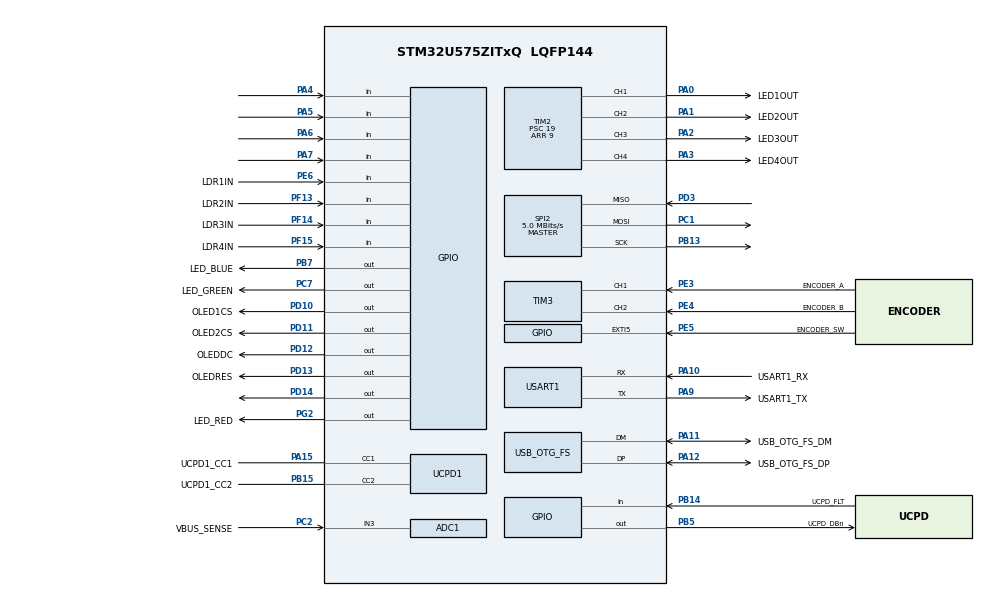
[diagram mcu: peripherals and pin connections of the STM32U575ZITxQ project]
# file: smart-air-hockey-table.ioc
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ADC1.NbrOfConversion=1
ADC1.Resolution=ADC_RESOLUTION_14B
ADC1.master=1
CORTEX_M33_NS.userName=CORTEX_M33
GPDMA1.CIRCULARMODE_GPDMACH0=DISABLE
GPDMA1.DATAHANDLING_GPDMACH0=ENABLE
GPDMA1.DATAHANDLING_GPDMACH1=ENABLE
GPDMA1.DATAHANDLING_GPDMACH2=ENABLE
GPDMA1.DATAHANDLING_GPDMACH3=ENABLE
GPDMA1.DESTDATAWIDTH_GPDMACH0=DMA_DEST_DATAWIDTH_WORD
GPDMA1.DESTDATAWIDTH_GPDMACH1=DMA_DEST_DATAWIDTH_WORD
GPDMA1.DESTDATAWIDTH_GPDMACH2=DMA_DEST_DATAWIDTH_WORD
GPDMA1.DESTDATAWIDTH_GPDMACH3=DMA_DEST_DATAWIDTH_WORD
GPDMA1.DIRECTION_GPDMACH0=DMA_MEMORY_TO_PERIPH
GPDMA1.DIRECTION_GPDMACH1=DMA_MEMORY_TO_PERIPH
GPDMA1.DIRECTION_GPDMACH2=DMA_MEMORY_TO_PERIPH
GPDMA1.DIRECTION_GPDMACH3=DMA_MEMORY_TO_PERIPH
GPDMA1.IPHANDLE_GPDMACH0-SIMPLEREQUEST_GPDMACH0=__NULL
GPDMA1.IPHANDLE_GPDMACH1-SIMPLEREQUEST_GPDMACH1=__NULL
GPDMA1.IPHANDLE_GPDMACH2-SIMPLEREQUEST_GPDMACH2=__NULL
GPDMA1.IPHANDLE_GPDMACH3-SIMPLEREQUEST_GPDMACH3=__NULL
GPDMA1.LINKALLOCATEDPORT_CIRCULAR_GPDMACH0=DMA_LINK_ALLOCATED_PORT1
GPDMA1.REQUEST_GPDMACH0=GPDMA1_REQUEST_TIM2_UP
GPDMA1.REQUEST_GPDMACH1=GPDMA1_REQUEST_TIM2_UP
GPDMA1.REQUEST_GPDMACH2=GPDMA1_REQUEST_TIM2_UP
GPDMA1.REQUEST_GPDMACH3=GPDMA1_REQUEST_TIM2_UP
GPDMA1.SRCDATAWIDTH_GPDMACH0=DMA_SRC_DATAWIDTH_BYTE
GPDMA1.SRCINC_GPDMACH0=DMA_SINC_INCREMENTED
GPDMA1.SRCINC_GPDMACH1=DMA_SINC_INCREMENTED
GPDMA1.SRCINC_GPDMACH2=DMA_SINC_INCREMENTED
GPDMA1.SRCINC_GPDMACH3=DMA_SINC_INCREMENTED
GPDMA1.TRANSFERALLOCATEDPORTSRC_GPDMACH0=DMA_SRC_ALLOCATED_PORT1
GPDMA1.TRANSFERALLOCATEDPORTSRC_GPDMACH1=DMA_SRC_ALLOCATED_PORT1
GPDMA1.TRANSFERALLOCATEDPORTSRC_GPDMACH2=DMA_SRC_ALLOCATED_PORT1
GPDMA1.TRANSFERALLOCATEDPORTSRC_GPDMACH3=DMA_SRC_ALLOCATED_PORT1
Mcu.Family=STM32U5
Mcu.Name=STM32U575ZITxQ
Mcu.Package=LQFP144
NVIC.EXTI5_IRQn=true\:3\:0\:true\:false\:true\:true\:true\:true
NVIC.GPDMA1_Channel0_IRQn=true\:3\:0\:true\:false\:true\:false\:true\:true
NVIC.GPDMA1_Channel1_IRQn=true\:3\:0\:true\:false\:true\:false\:true\:true
NVIC.GPDMA1_Channel2_IRQn=true\:3\:0\:true\:false\:true\:false\:true\:true
NVIC.GPDMA1_Channel3_IRQn=true\:3\:0\:true\:false\:true\:false\:true\:true
NVIC.OTG_FS_IRQn=true\:0\:0\:false\:false\:true\:true\:true\:true
NVIC.PriorityGroup=NVIC_PRIORITYGROUP_3
NVIC.TIM6_IRQn=true\:1\:0\:true\:false\:true\:true\:true\:true
NVIC.TIM7_IRQn=true\:2\:0\:true\:false\:true\:true\:true\:true
PA0.GPIO_Label=LED1OUT
PA0.Signal=S_TIM2_CH1
PA1.GPIO_Label=LED2OUT
PA1.Signal=S_TIM2_CH2
PA10.GPIO_Label=USART1_RX
PA10.GPIO_PuPd=GPIO_PULLDOWN
PA10.GPIO_Speed=GPIO_SPEED_FREQ_VERY_HIGH
PA10.Mode=Asynchronous
PA10.Signal=USART1_RX
PA11.GPIO_Label=USB_OTG_FS_DM
PA11.GPIO_Speed=GPIO_SPEED_FREQ_VERY_HIGH
PA11.Mode=Device_Only
PA11.Signal=USB_OTG_FS_DM
PA12.GPIO_Label=USB_OTG_FS_DP
PA12.GPIO_Speed=GPIO_SPEED_FREQ_VERY_HIGH
PA12.Mode=Device_Only
PA12.Signal=USB_OTG_FS_DP
PA13\ (JTMS/SWDIO).Mode=Trace_Asynchronous_SW
PA13\ (JTMS/SWDIO).Signal=DEBUG_JTMS-SWDIO
PA14\ (JTCK/SWCLK).Mode=Trace_Asynchronous_SW
PA14\ (JTCK/SWCLK).Signal=DEBUG_JTCK-SWCLK
PA15\ (JTDI).GPIO_Label=UCPD1_CC1
PA15\ (JTDI).Mode=Sink_AllSignals
PA15\ (JTDI).Signal=UCPD1_CC1
PA2.GPIO_Label=LED3OUT
PA2.Signal=S_TIM2_CH3
PA3.GPIO_Label=LED4OUT
PA3.Signal=S_TIM2_CH4
PA4.GPIO_PuPd=GPIO_PULLUP
PA4.Signal=GPIO_Input
PA5.GPIO_PuPd=GPIO_PULLUP
PA5.Signal=GPIO_Input
PA6.GPIO_PuPd=GPIO_PULLUP
PA6.Signal=GPIO_Input
PA7.GPIO_PuPd=GPIO_PULLUP
PA7.Signal=GPIO_Input
PA9.GPIO_Label=USART1_TX
PA9.GPIO_PuPd=GPIO_PULLDOWN
PA9.GPIO_Speed=GPIO_SPEED_FREQ_VERY_HIGH
PA9.Mode=Asynchronous
PA9.Signal=USART1_TX
PB13.Mode=Full_Duplex_Master
PB13.Signal=SPI2_SCK
PB14.GPIO_Label=UCPD_FLT
PB14.Signal=GPIO_Input
PB15.GPIO_Label=UCPD1_CC2
PB15.Mode=Sink_AllSignals
PB15.Signal=UCPD1_CC2
PB3\ (JTDO/TRACESWO).Mode=Trace_Asynchronous_SW
PB3\ (JTDO/TRACESWO).Signal=DEBUG_JTDO-SWO
PB5.GPIO_Label=UCPD_DBn
PB5.Signal=GPIO_Output
PB7.GPIO_Label=LED_BLUE
PB7.GPIO_ModeDefaultOutputPP=GPIO_MODE_OUTPUT_PP
PB7.GPIO_PuPd=GPIO_PULLUP
PB7.GPIO_Speed=GPIO_SPEED_FREQ_HIGH
PB7.Signal=GPIO_Output
PC1.Mode=Full_Duplex_Master
PC1.Signal=SPI2_MOSI
PC14-OSC32_IN\ (PC14).Mode=LSE-External-Oscillator
PC14-OSC32_IN\ (PC14).Signal=RCC_OSC32_IN
PC15-OSC32_OUT\ (PC15).Mode=LSE-External-Oscillator
PC15-OSC32_OUT\ (PC15).Signal=RCC_OSC32_OUT
PC2.GPIO_Label=VBUS_SENSE
PC2.Mode=IN3-Single-Ended
PC2.Signal=ADC1_IN3
PC7.GPIO_Label=LED_GREEN
PC7.GPIO_PuPd=GPIO_PULLUP
PC7.GPIO_Speed=GPIO_SPEED_FREQ_HIGH
PC7.Signal=GPIO_Output
PD10.GPIO_Label=OLED1CS
PD10.Signal=GPIO_Output
PD11.GPIO_Label=OLED2CS
PD11.Signal=GPIO_Output
PD12.GPIO_Label=OLEDDC
PD12.Signal=GPIO_Output
PD13.GPIO_Label=OLEDRES
PD13.Signal=GPIO_Output
PD14.Signal=GPIO_Output
PD3.Mode=Full_Duplex_Master
PD3.Signal=SPI2_MISO
PE3.GPIO_Label=ENCODER_A
PE3.GPIO_PuPd=GPIO_PULLUP
PE3.Signal=S_TIM3_CH1
PE4.GPIO_Label=ENCODER_B
PE4.GPIO_PuPd=GPIO_PULLUP
PE4.Signal=S_TIM3_CH2
PE5.GPIO_Label=ENCODER_SW
PE5.GPIO_ModeDefaultEXTI=GPIO_MODE_IT_FALLING
PE5.GPIO_PuPd=GPIO_PULLUP
PE5.Signal=GPXTI5
PE6.GPIO_Label=LDR1IN
PE6.Signal=GPIO_Input
PF13.GPIO_Label=LDR2IN
PF13.Signal=GPIO_Input
PF14.GPIO_Label=LDR3IN
PF14.Signal=GPIO_Input
PF15.GPIO_Label=LDR4IN
PF15.Signal=GPIO_Input
PG2.GPIO_Label=LED_RED
PG2.GPIO_ModeDefaultOutputPP=GPIO_MODE_OUTPUT_PP
PG2.GPIO_PuPd=GPIO_PULLUP
PG2.GPIO_Speed=GPIO_SPEED_FREQ_HIGH
PG2.Signal=GPIO_Output
PWR.PowerMode=PWR_SMPS_SUPPLY
ProjectManager.HeapSize=0x200
ProjectManager.StackSize=0x400
ProjectManager.TargetToolchain=STM32CubeIDE
RCC.ADCFreq_Value=16000000
RCC.AHBFreq_Value=160000000
RCC.APB1Freq_Value=160000000
RCC.APB1TimFreq_Value=160000000
RCC.APB2Freq_Value=160000000
RCC.APB2TimFreq_Value=160000000
RCC.APB3Freq_Value=160000000
RCC.CortexFreq_Value=160000000
RCC.DACCLockSelectionVirtual=RCC_DAC1CLKSOURCE_LSI
RCC.EPOD_VALUE=4000000
RCC.HCLKFreq_Value=160000000
RCC.HSE_VALUE=16000000
RCC.HSI48_VALUE=48000000
RCC.HSI_VALUE=16000000
RCC.LSIDIV_VALUE=32000
RCC.MSI_VALUE=4000000
RCC.PLLN=80
RCC.SYSCLKFreq_VALUE=160000000
RCC.SYSCLKSource=RCC_SYSCLKSOURCE_PLLCLK
RCC.USBFreq_Value=48000000
RCC.VCOOutputFreq_Value=320000000
SH.S_TIM2_CH1.0=TIM2_CH1,PWM Generation1 CH1
SH.S_TIM2_CH2.0=TIM2_CH2,PWM Generation2 CH2
SH.S_TIM2_CH3.0=TIM2_CH3,PWM Generation3 CH3
SH.S_TIM2_CH4.0=TIM2_CH4,PWM Generation4 CH4
SH.S_TIM3_CH1.0=TIM3_CH1,Encoder_Interface
SH.S_TIM3_CH2.0=TIM3_CH2,Encoder_Interface
SPI2.BaudRatePrescaler=SPI_BAUDRATEPRESCALER_32
SPI2.CalculateBaudRate=5.0 MBits/s
SPI2.DataSize=SPI_DATASIZE_8BIT
SPI2.Direction=SPI_DIRECTION_2LINES
SPI2.Mode=SPI_MODE_MASTER
SPI2.VirtualType=VM_MASTER
TIM2.Channel-PWM\ Generation1\ CH1=TIM_CHANNEL_1
TIM2.Channel-PWM\ Generation2\ CH2=TIM_CHANNEL_2
TIM2.Channel-PWM\ Generation3\ CH3=TIM_CHANNEL_3
TIM2.Channel-PWM\ Generation4\ CH4=TIM_CHANNEL_4
TIM2.PeriodNoDither=9
TIM2.Prescaler=19
TIM2.PulseNoDither_1=0
TIM2.TIM_MasterOutputTrigger=TIM_TRGO_RESET
TIM3.EncoderMode=TIM_ENCODERMODE_TI12
TIM3.IC1Filter=8
TIM3.IC2Filter=8
TIM6.PeriodNoDither=9
TIM6.Prescaler=15999
TIM7.PeriodNoDither=9
TIM7.Prescaler=15999
USART1.VirtualMode-Asynchronous=VM_ASYNC
USB_OTG_FS.VirtualMode=Device_Only
VP_GPDMA1_VS_GPDMACH0.Mode=SIMPLEREQUEST_GPDMACH0
VP_GPDMA1_VS_GPDMACH1.Mode=SIMPLEREQUEST_GPDMACH1
VP_GPDMA1_VS_GPDMACH2.Mode=SIMPLEREQUEST_GPDMACH2
VP_GPDMA1_VS_GPDMACH3.Mode=SIMPLEREQUEST_GPDMACH3
VP_ICACHE_VS_ICACHE.Mode=DirectMappedCache
VP_LPBAMQUEUE_VS_QUEUE.Mode=QUEUEMODE
VP_LPBAM_VS_SIG1.Mode=SmartRun
VP_LPBAM_VS_SIG4.Mode=LPDMA1
VP_MEMORYMAP_VS_MEMORYMAP.Mode=CurAppReg
VP_PWR_VS_DBSignals.Mode=DisableDeadBatterySignals
VP_PWR_VS_LPOM.Mode=PowerOptimisation
VP_PWR_VS_SECSignals.Mode=Security/Privilege
VP_PWR_Vdda.Mode=isolationVdda
VP_TIM2_VS_ClockSourceINT.Mode=Internal
VP_TIM6_VS_ClockSourceINT.Mode=Enable_Timer
VP_TIM7_VS_ClockSourceINT.Mode=Enable_Timer
board=NUCLEO-U575ZI-Q

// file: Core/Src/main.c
/* USER CODE BEGIN Header */
/**
  ******************************************************************************
  * @file           : main.c
  * @brief          : Main program body
  ******************************************************************************
  * @attention
  *
  * Copyright (c) 2023 STMicroelectronics.
  * All rights reserved.
  *
  * This software is licensed under terms that can be found in the LICENSE file
  * in the root directory of this software component.
  * If no LICENSE file comes with this software, it is provided AS-IS.
  *
  ******************************************************************************
  */
/* USER CODE END Header */
#include "main.h"

/* USER CODE BEGIN Includes */
#include "app_core.h"
/* USER CODE END Includes */

PCD_HandleTypeDef hpcd_USB_OTG_FS;

void SystemClock_Config(void);
static void SystemPower_Config(void);
static void MX_GPIO_Init(void);
static void MX_GPDMA1_Init(void);
static void MX_ICACHE_Init(void);
static void MX_UCPD1_Init(void);
static void MX_USART1_UART_Init(void);
static void MX_USB_OTG_FS_PCD_Init(void);
static void MX_MEMORYMAP_Init(void);
static void MX_TIM2_Init(void);
static void MX_ADC1_Init(void);
static void MX_SPI2_Init(void);
static void MX_TIM3_Init(void);
static void MX_TIM6_Init(void);
static void MX_TIM7_Init(void);

int main(void)
{

  /* MCU Configuration--------------------------------------------------------*/

  /* Reset of all peripherals, Initializes the Flash interface and the Systick. */
  HAL_Init();

  /* Enable PWR clock interface */

  LL_AHB3_GRP1_EnableClock(LL_AHB3_GRP1_PERIPH_PWR);

  /* USER CODE BEGIN Init */
  /* Enable the independent analog and I/Os supply */
  LL_PWR_EnableVDDA();

  /* USER CODE END Init */

  /* Configure the system clock */
  SystemClock_Config();

  /* Configure the System Power */
  SystemPower_Config();

  /* Initialize all configured peripherals */
  MX_GPIO_Init();
  MX_GPDMA1_Init();
  MX_ICACHE_Init();
  MX_UCPD1_Init();
  MX_USART1_UART_Init();
  MX_USB_OTG_FS_PCD_Init();
  MX_MEMORYMAP_Init();
  MX_TIM2_Init();
  MX_ADC1_Init();
  MX_SPI2_Init();
  MX_TIM3_Init();
  MX_TIM6_Init();
  MX_TIM7_Init();
  /* USER CODE BEGIN 2 */
  App_Init();
  /* USER CODE END 2 */

  /* Infinite loop */
  while (1)
  {

    /* USER CODE BEGIN 3 */
    asm("wfi");
  }
  /* USER CODE END 3 */
}

void SystemClock_Config(void)
{
  LL_FLASH_SetLatency(LL_FLASH_LATENCY_4);
  while(LL_FLASH_GetLatency()!= LL_FLASH_LATENCY_4)
  {
  }

  LL_PWR_SetRegulVoltageScaling(LL_PWR_REGU_VOLTAGE_SCALE1);
  while (LL_PWR_IsActiveFlag_VOS() == 0)
  {
  }
  LL_RCC_HSI_Enable();

   /* Wait till HSI is ready */
  while(LL_RCC_HSI_IsReady() != 1)
  {
  }

  LL_RCC_HSI_SetCalibTrimming(16);
  LL_RCC_HSI48_Enable();

   /* Wait till HSI48 is ready */
  while(LL_RCC_HSI48_IsReady() != 1)
  {
  }

  LL_RCC_MSIS_Enable();

   /* Wait till MSIS is ready */
  while(LL_RCC_MSIS_IsReady() != 1)
  {
  }

  LL_RCC_MSI_EnableRangeSelection();
  LL_RCC_MSIS_SetRange(LL_RCC_MSISRANGE_4);
  LL_RCC_MSI_SetCalibTrimming(16, LL_RCC_MSI_OSCILLATOR_1);
  LL_RCC_PLL1_ConfigDomain_SYS(LL_RCC_PLL1SOURCE_MSIS, 1, 80, 2);
  LL_RCC_PLL1_EnableDomain_SYS();
  LL_RCC_SetPll1EPodPrescaler(LL_RCC_PLL1MBOOST_DIV_1);
  LL_RCC_PLL1_SetVCOInputRange(LL_RCC_PLLINPUTRANGE_4_8);
  LL_RCC_PLL1_Enable();

   /* Wait till PLL is ready */
  while(LL_RCC_PLL1_IsReady() != 1)
  {
  }

   /* Intermediate AHB prescaler 2 when target frequency clock is higher than 80 MHz */
  LL_RCC_SetAHBPrescaler(LL_RCC_SYSCLK_DIV_2);

  LL_RCC_SetSysClkSource(LL_RCC_SYS_CLKSOURCE_PLL1);

   /* Wait till System clock is ready */
  while(LL_RCC_GetSysClkSource() != LL_RCC_SYS_CLKSOURCE_STATUS_PLL1)
  {
  }

  /* Insure 1us transition state at intermediate medium speed clock*/
  for (__IO uint32_t i = (160 >> 1); i !=0; i--);

  LL_RCC_SetAHBPrescaler(LL_RCC_SYSCLK_DIV_1);
  LL_RCC_SetAPB1Prescaler(LL_RCC_APB1_DIV_1);
  LL_RCC_SetAPB2Prescaler(LL_RCC_APB2_DIV_1);
  LL_RCC_SetAPB3Prescaler(LL_RCC_APB3_DIV_1);
  LL_SetSystemCoreClock(160000000);

   /* Update the time base */
  if (HAL_InitTick (TICK_INT_PRIORITY) != HAL_OK)
  {
    Error_Handler();
  }
}

/**
  * @brief Power Configuration
  * @retval None
  */
static void SystemPower_Config(void)
{

  /*
   * Switch to SMPS regulator instead of LDO
   */
  LL_PWR_SetRegulatorSupply(LL_PWR_SMPS_SUPPLY);

  while(LL_PWR_IsActiveFlag_REGULATOR()!=1)
  {
  }
}

static void MX_ADC1_Init(void)
{

  LL_ADC_CommonInitTypeDef ADC_CommonInitStruct = {0};
  LL_ADC_InitTypeDef ADC_InitStruct = {0};
  LL_ADC_REG_InitTypeDef ADC_REG_InitStruct = {0};

  LL_GPIO_InitTypeDef GPIO_InitStruct = {0};

  LL_RCC_SetADCDACClockSource(LL_RCC_ADCDAC_CLKSOURCE_HSI);

  /* Peripheral clock enable */
  LL_AHB2_GRP1_EnableClock(LL_AHB2_GRP1_PERIPH_ADC12);

  LL_AHB2_GRP1_EnableClock(LL_AHB2_GRP1_PERIPH_GPIOC);
  /**ADC1 GPIO Configuration
  PC2   ------> ADC1_IN3
  */
  GPIO_InitStruct.Pin = VBUS_SENSE_Pin;
  GPIO_InitStruct.Mode = LL_GPIO_MODE_ANALOG;
  GPIO_InitStruct.Pull = LL_GPIO_PULL_NO;
  LL_GPIO_Init(VBUS_SENSE_GPIO_Port, &GPIO_InitStruct);

  /** Common config
  */
  LL_ADC_SetTriggerFrequencyMode(ADC1, LL_ADC_TRIGGER_FREQ_HIGH);
  ADC_CommonInitStruct.CommonClock = LL_ADC_CLOCK_ASYNC_DIV1;
  LL_ADC_CommonInit(__LL_ADC_COMMON_INSTANCE(ADC1), &ADC_CommonInitStruct);
  ADC_InitStruct.Resolution = LL_ADC_RESOLUTION_14B;
  ADC_InitStruct.LowPowerMode = LL_ADC_LP_MODE_NONE;
  ADC_InitStruct.LeftBitShift = LL_ADC_LEFT_BIT_SHIFT_NONE;
  LL_ADC_Init(ADC1, &ADC_InitStruct);
  LL_ADC_SetGainCompensation(ADC1, 0);
  ADC_REG_InitStruct.SequencerLength = LL_ADC_REG_SEQ_SCAN_DISABLE;
  ADC_REG_InitStruct.SequencerDiscont = LL_ADC_REG_SEQ_DISCONT_DISABLE;
  ADC_REG_InitStruct.ContinuousMode = LL_ADC_REG_CONV_SINGLE;
  ADC_REG_InitStruct.Overrun = LL_ADC_REG_OVR_DATA_PRESERVED;
  ADC_REG_InitStruct.DataTransferMode = LL_ADC_REG_DR_TRANSFER;
  LL_ADC_REG_Init(ADC1, &ADC_REG_InitStruct);
  LL_ADC_SetOverSamplingScope(ADC1, LL_ADC_OVS_DISABLE);

  /* Disable ADC deep power down (enabled by default after reset state) */
  LL_ADC_DisableDeepPowerDown(ADC1);
  /* Enable ADC internal voltage regulator */
  LL_ADC_EnableInternalRegulator(ADC1);
  /* Delay for ADC internal voltage regulator stabilization. */
  /* Compute number of CPU cycles to wait for, from delay in us. */
  /* Note: Variable divided by 2 to compensate partially */
  /* CPU processing cycles (depends on compilation optimization). */
  /* Note: If system core clock frequency is below 200kHz, wait time */
  /* is only a few CPU processing cycles. */
  __IO uint32_t wait_loop_index;
  wait_loop_index = ((LL_ADC_DELAY_INTERNAL_REGUL_STAB_US * (SystemCoreClock / (100000 * 2))) / 10);
  while(wait_loop_index != 0)
  {
    wait_loop_index--;
  }

}

static void MX_GPDMA1_Init(void)
{

  /* Peripheral clock enable */
  LL_AHB1_GRP1_EnableClock(LL_AHB1_GRP1_PERIPH_GPDMA1);

  /* GPDMA1 interrupt Init */
  NVIC_SetPriority(GPDMA1_Channel0_IRQn, NVIC_EncodePriority(NVIC_GetPriorityGrouping(),3, 0));
  NVIC_EnableIRQ(GPDMA1_Channel0_IRQn);
  NVIC_SetPriority(GPDMA1_Channel1_IRQn, NVIC_EncodePriority(NVIC_GetPriorityGrouping(),3, 0));
  NVIC_EnableIRQ(GPDMA1_Channel1_IRQn);
  NVIC_SetPriority(GPDMA1_Channel2_IRQn, NVIC_EncodePriority(NVIC_GetPriorityGrouping(),3, 0));
  NVIC_EnableIRQ(GPDMA1_Channel2_IRQn);
  NVIC_SetPriority(GPDMA1_Channel3_IRQn, NVIC_EncodePriority(NVIC_GetPriorityGrouping(),3, 0));
  NVIC_EnableIRQ(GPDMA1_Channel3_IRQn);

}

static void MX_ICACHE_Init(void)
{

  /** Enable instruction cache in 1-way (direct mapped cache)
  */
  LL_ICACHE_SetMode(LL_ICACHE_1WAY);
  LL_ICACHE_Enable();

}

static void MX_MEMORYMAP_Init(void)
{

}

static void MX_SPI2_Init(void)
{

  LL_SPI_InitTypeDef SPI_InitStruct = {0};

  LL_GPIO_InitTypeDef GPIO_InitStruct = {0};

  LL_RCC_SetSPIClockSource(LL_RCC_SPI2_CLKSOURCE_SYSCLK);

  /* Peripheral clock enable */
  LL_APB1_GRP1_EnableClock(LL_APB1_GRP1_PERIPH_SPI2);

  LL_AHB2_GRP1_EnableClock(LL_AHB2_GRP1_PERIPH_GPIOC);
  LL_AHB2_GRP1_EnableClock(LL_AHB2_GRP1_PERIPH_GPIOB);
  LL_AHB2_GRP1_EnableClock(LL_AHB2_GRP1_PERIPH_GPIOD);
  /**SPI2 GPIO Configuration
  PC1   ------> SPI2_MOSI
  PB13   ------> SPI2_SCK
  PD3   ------> SPI2_MISO
  */
  GPIO_InitStruct.Pin = LL_GPIO_PIN_1;
  GPIO_InitStruct.Mode = LL_GPIO_MODE_ALTERNATE;
  GPIO_InitStruct.Speed = LL_GPIO_SPEED_FREQ_LOW;
  GPIO_InitStruct.OutputType = LL_GPIO_OUTPUT_PUSHPULL;
  GPIO_InitStruct.Pull = LL_GPIO_PULL_NO;
  GPIO_InitStruct.Alternate = LL_GPIO_AF_3;
  LL_GPIO_Init(GPIOC, &GPIO_InitStruct);

  GPIO_InitStruct.Pin = LL_GPIO_PIN_13;
  GPIO_InitStruct.Mode = LL_GPIO_MODE_ALTERNATE;
  GPIO_InitStruct.Speed = LL_GPIO_SPEED_FREQ_LOW;
  GPIO_InitStruct.OutputType = LL_GPIO_OUTPUT_PUSHPULL;
  GPIO_InitStruct.Pull = LL_GPIO_PULL_NO;
  GPIO_InitStruct.Alternate = LL_GPIO_AF_5;
  LL_GPIO_Init(GPIOB, &GPIO_InitStruct);

  GPIO_InitStruct.Pin = LL_GPIO_PIN_3;
  GPIO_InitStruct.Mode = LL_GPIO_MODE_ALTERNATE;
  GPIO_InitStruct.Speed = LL_GPIO_SPEED_FREQ_LOW;
  GPIO_InitStruct.OutputType = LL_GPIO_OUTPUT_PUSHPULL;
  GPIO_InitStruct.Pull = LL_GPIO_PULL_NO;
  GPIO_InitStruct.Alternate = LL_GPIO_AF_5;
  LL_GPIO_Init(GPIOD, &GPIO_InitStruct);

  /* SPI2 parameter configuration*/
  SPI_InitStruct.TransferDirection = LL_SPI_FULL_DUPLEX;
  SPI_InitStruct.Mode = LL_SPI_MODE_MASTER;
  SPI_InitStruct.DataWidth = LL_SPI_DATAWIDTH_8BIT;
  SPI_InitStruct.ClockPolarity = LL_SPI_POLARITY_LOW;
  SPI_InitStruct.ClockPhase = LL_SPI_PHASE_1EDGE;
  SPI_InitStruct.NSS = LL_SPI_NSS_SOFT;
  SPI_InitStruct.BaudRate = LL_SPI_BAUDRATEPRESCALER_DIV32;
  SPI_InitStruct.BitOrder = LL_SPI_MSB_FIRST;
  SPI_InitStruct.CRCCalculation = LL_SPI_CRCCALCULATION_DISABLE;
  SPI_InitStruct.CRCPoly = 0x7;
  LL_SPI_Init(SPI2, &SPI_InitStruct);
  LL_SPI_SetStandard(SPI2, LL_SPI_PROTOCOL_MOTOROLA);
  LL_SPI_EnableNSSPulseMgt(SPI2);

}

static void MX_TIM2_Init(void)
{

  LL_TIM_InitTypeDef TIM_InitStruct = {0};
  LL_TIM_OC_InitTypeDef TIM_OC_InitStruct = {0};

  LL_DMA_InitTypeDef DMA_InitStruct = {0};
  LL_GPIO_InitTypeDef GPIO_InitStruct = {0};

  /* Peripheral clock enable */
  LL_APB1_GRP1_EnableClock(LL_APB1_GRP1_PERIPH_TIM2);

  /* TIM2 DMA Init */

  /* GPDMA1_REQUEST_TIM2_UP Init */
  DMA_InitStruct.SrcAddress = 0x00000000U;
  DMA_InitStruct.DestAddress = 0x00000000U;
  DMA_InitStruct.Direction = LL_DMA_DIRECTION_MEMORY_TO_PERIPH;
  DMA_InitStruct.BlkHWRequest = LL_DMA_HWREQUEST_SINGLEBURST;
  DMA_InitStruct.DataAlignment = LL_DMA_DATA_ALIGN_ZEROPADD;
  DMA_InitStruct.SrcBurstLength = 1;
  DMA_InitStruct.DestBurstLength = 1;
  DMA_InitStruct.SrcDataWidth = LL_DMA_SRC_DATAWIDTH_BYTE;
  DMA_InitStruct.DestDataWidth = LL_DMA_DEST_DATAWIDTH_WORD;
  DMA_InitStruct.SrcIncMode = LL_DMA_SRC_INCREMENT;
  DMA_InitStruct.DestIncMode = LL_DMA_DEST_FIXED;
  DMA_InitStruct.Priority = LL_DMA_LOW_PRIORITY_LOW_WEIGHT;
  DMA_InitStruct.BlkDataLength = 0x00000000U;
  DMA_InitStruct.TriggerMode = LL_DMA_TRIGM_BLK_TRANSFER;
  DMA_InitStruct.TriggerPolarity = LL_DMA_TRIG_POLARITY_MASKED;
  DMA_InitStruct.TriggerSelection = 0x00000000U;
  DMA_InitStruct.Request = LL_GPDMA1_REQUEST_TIM2_UP;
  DMA_InitStruct.TransferEventMode = LL_DMA_TCEM_BLK_TRANSFER;
  DMA_InitStruct.SrcAllocatedPort = LL_DMA_SRC_ALLOCATED_PORT1;
  DMA_InitStruct.DestAllocatedPort = LL_DMA_DEST_ALLOCATED_PORT0;
  DMA_InitStruct.LinkAllocatedPort = LL_DMA_LINK_ALLOCATED_PORT1;
  DMA_InitStruct.LinkStepMode = LL_DMA_LSM_FULL_EXECUTION;
  DMA_InitStruct.LinkedListBaseAddr = 0x00000000U;
  DMA_InitStruct.LinkedListAddrOffset = 0x00000000U;
  LL_DMA_Init(GPDMA1, LL_DMA_CHANNEL_3, &DMA_InitStruct);

  /* GPDMA1_REQUEST_TIM2_UP Init */
  DMA_InitStruct.SrcAddress = 0x00000000U;
  DMA_InitStruct.DestAddress = 0x00000000U;
  DMA_InitStruct.Direction = LL_DMA_DIRECTION_MEMORY_TO_PERIPH;
  DMA_InitStruct.BlkHWRequest = LL_DMA_HWREQUEST_SINGLEBURST;
  DMA_InitStruct.DataAlignment = LL_DMA_DATA_ALIGN_ZEROPADD;
  DMA_InitStruct.SrcBurstLength = 1;
  DMA_InitStruct.DestBurstLength = 1;
  DMA_InitStruct.SrcDataWidth = LL_DMA_SRC_DATAWIDTH_BYTE;
  DMA_InitStruct.DestDataWidth = LL_DMA_DEST_DATAWIDTH_WORD;
  DMA_InitStruct.SrcIncMode = LL_DMA_SRC_INCREMENT;
  DMA_InitStruct.DestIncMode = LL_DMA_DEST_FIXED;
  DMA_InitStruct.Priority = LL_DMA_LOW_PRIORITY_LOW_WEIGHT;
  DMA_InitStruct.BlkDataLength = 0x00000000U;
  DMA_InitStruct.TriggerMode = LL_DMA_TRIGM_BLK_TRANSFER;
  DMA_InitStruct.TriggerPolarity = LL_DMA_TRIG_POLARITY_MASKED;
  DMA_InitStruct.TriggerSelection = 0x00000000U;
  DMA_InitStruct.Request = LL_GPDMA1_REQUEST_TIM2_UP;
  DMA_InitStruct.TransferEventMode = LL_DMA_TCEM_BLK_TRANSFER;
  DMA_InitStruct.SrcAllocatedPort = LL_DMA_SRC_ALLOCATED_PORT1;
  DMA_InitStruct.DestAllocatedPort = LL_DMA_DEST_ALLOCATED_PORT0;
  DMA_InitStruct.LinkAllocatedPort = LL_DMA_LINK_ALLOCATED_PORT1;
  DMA_InitStruct.LinkStepMode = LL_DMA_LSM_FULL_EXECUTION;
  DMA_InitStruct.LinkedListBaseAddr = 0x00000000U;
  DMA_InitStruct.LinkedListAddrOffset = 0x00000000U;
  LL_DMA_Init(GPDMA1, LL_DMA_CHANNEL_2, &DMA_InitStruct);

  /* GPDMA1_REQUEST_TIM2_UP Init */
  DMA_InitStruct.SrcAddress = 0x00000000U;
  DMA_InitStruct.DestAddress = 0x00000000U;
  DMA_InitStruct.Direction = LL_DMA_DIRECTION_MEMORY_TO_PERIPH;
  DMA_InitStruct.BlkHWRequest = LL_DMA_HWREQUEST_SINGLEBURST;
  DMA_InitStruct.DataAlignment = LL_DMA_DATA_ALIGN_ZEROPADD;
  DMA_InitStruct.SrcBurstLength = 1;
  DMA_InitStruct.DestBurstLength = 1;
  DMA_InitStruct.SrcDataWidth = LL_DMA_SRC_DATAWIDTH_BYTE;
  DMA_InitStruct.DestDataWidth = LL_DMA_DEST_DATAWIDTH_WORD;
  DMA_InitStruct.SrcIncMode = LL_DMA_SRC_INCREMENT;
  DMA_InitStruct.DestIncMode = LL_DMA_DEST_FIXED;
  DMA_InitStruct.Priority = LL_DMA_LOW_PRIORITY_LOW_WEIGHT;
  DMA_InitStruct.BlkDataLength = 0x00000000U;
  DMA_InitStruct.TriggerMode = LL_DMA_TRIGM_BLK_TRANSFER;
  DMA_InitStruct.TriggerPolarity = LL_DMA_TRIG_POLARITY_MASKED;
  DMA_InitStruct.TriggerSelection = 0x00000000U;
  DMA_InitStruct.Request = LL_GPDMA1_REQUEST_TIM2_UP;
  DMA_InitStruct.TransferEventMode = LL_DMA_TCEM_BLK_TRANSFER;
  DMA_InitStruct.SrcAllocatedPort = LL_DMA_SRC_ALLOCATED_PORT1;
  DMA_InitStruct.DestAllocatedPort = LL_DMA_DEST_ALLOCATED_PORT0;
  DMA_InitStruct.LinkAllocatedPort = LL_DMA_LINK_ALLOCATED_PORT1;
  DMA_InitStruct.LinkStepMode = LL_DMA_LSM_FULL_EXECUTION;
  DMA_InitStruct.LinkedListBaseAddr = 0x00000000U;
  DMA_InitStruct.LinkedListAddrOffset = 0x00000000U;
  LL_DMA_Init(GPDMA1, LL_DMA_CHANNEL_1, &DMA_InitStruct);

  /* GPDMA1_REQUEST_TIM2_UP Init */
  DMA_InitStruct.SrcAddress = 0x00000000U;
  DMA_InitStruct.DestAddress = 0x00000000U;
  DMA_InitStruct.Direction = LL_DMA_DIRECTION_MEMORY_TO_PERIPH;
  DMA_InitStruct.BlkHWRequest = LL_DMA_HWREQUEST_SINGLEBURST;
  DMA_InitStruct.DataAlignment = LL_DMA_DATA_ALIGN_ZEROPADD;
  DMA_InitStruct.SrcBurstLength = 1;
  DMA_InitStruct.DestBurstLength = 1;
  DMA_InitStruct.SrcDataWidth = LL_DMA_SRC_DATAWIDTH_BYTE;
  DMA_InitStruct.DestDataWidth = LL_DMA_DEST_DATAWIDTH_WORD;
  DMA_InitStruct.SrcIncMode = LL_DMA_SRC_INCREMENT;
  DMA_InitStruct.DestIncMode = LL_DMA_DEST_FIXED;
  DMA_InitStruct.Priority = LL_DMA_LOW_PRIORITY_LOW_WEIGHT;
  DMA_InitStruct.BlkDataLength = 0x00000000U;
  DMA_InitStruct.TriggerMode = LL_DMA_TRIGM_BLK_TRANSFER;
  DMA_InitStruct.TriggerPolarity = LL_DMA_TRIG_POLARITY_MASKED;
  DMA_InitStruct.TriggerSelection = 0x00000000U;
  DMA_InitStruct.Request = LL_GPDMA1_REQUEST_TIM2_UP;
  DMA_InitStruct.TransferEventMode = LL_DMA_TCEM_BLK_TRANSFER;
  DMA_InitStruct.SrcAllocatedPort = LL_DMA_SRC_ALLOCATED_PORT1;
  DMA_InitStruct.DestAllocatedPort = LL_DMA_DEST_ALLOCATED_PORT0;
  DMA_InitStruct.LinkAllocatedPort = LL_DMA_LINK_ALLOCATED_PORT1;
  DMA_InitStruct.LinkStepMode = LL_DMA_LSM_FULL_EXECUTION;
  DMA_InitStruct.LinkedListBaseAddr = 0x00000000U;
  DMA_InitStruct.LinkedListAddrOffset = 0x00000000U;
  LL_DMA_Init(GPDMA1, LL_DMA_CHANNEL_0, &DMA_InitStruct);

  TIM_InitStruct.Prescaler = 19;
  TIM_InitStruct.CounterMode = LL_TIM_COUNTERMODE_UP;
  TIM_InitStruct.Autoreload = 9;
  TIM_InitStruct.ClockDivision = LL_TIM_CLOCKDIVISION_DIV1;
  LL_TIM_Init(TIM2, &TIM_InitStruct);
  LL_TIM_DisableARRPreload(TIM2);
  LL_TIM_SetClockSource(TIM2, LL_TIM_CLOCKSOURCE_INTERNAL);
  LL_TIM_OC_EnablePreload(TIM2, LL_TIM_CHANNEL_CH1);
  TIM_OC_InitStruct.OCMode = LL_TIM_OCMODE_PWM1;
  TIM_OC_InitStruct.OCState = LL_TIM_OCSTATE_DISABLE;
  TIM_OC_InitStruct.OCNState = LL_TIM_OCSTATE_DISABLE;
  TIM_OC_InitStruct.CompareValue = 0;
  TIM_OC_InitStruct.OCPolarity = LL_TIM_OCPOLARITY_HIGH;
  LL_TIM_OC_Init(TIM2, LL_TIM_CHANNEL_CH1, &TIM_OC_InitStruct);
  LL_TIM_OC_DisableFast(TIM2, LL_TIM_CHANNEL_CH1);
  LL_TIM_OC_EnablePreload(TIM2, LL_TIM_CHANNEL_CH2);
  LL_TIM_OC_Init(TIM2, LL_TIM_CHANNEL_CH2, &TIM_OC_InitStruct);
  LL_TIM_OC_DisableFast(TIM2, LL_TIM_CHANNEL_CH2);
  LL_TIM_OC_EnablePreload(TIM2, LL_TIM_CHANNEL_CH3);
  LL_TIM_OC_Init(TIM2, LL_TIM_CHANNEL_CH3, &TIM_OC_InitStruct);
  LL_TIM_OC_DisableFast(TIM2, LL_TIM_CHANNEL_CH3);
  LL_TIM_OC_EnablePreload(TIM2, LL_TIM_CHANNEL_CH4);
  LL_TIM_OC_Init(TIM2, LL_TIM_CHANNEL_CH4, &TIM_OC_InitStruct);
  LL_TIM_OC_DisableFast(TIM2, LL_TIM_CHANNEL_CH4);
  LL_TIM_SetTriggerOutput(TIM2, LL_TIM_TRGO_RESET);
  LL_TIM_DisableMasterSlaveMode(TIM2);
  LL_AHB2_GRP1_EnableClock(LL_AHB2_GRP1_PERIPH_GPIOA);
  /**TIM2 GPIO Configuration
  PA0   ------> TIM2_CH1
  PA1   ------> TIM2_CH2
  PA2   ------> TIM2_CH3
  PA3   ------> TIM2_CH4
  */
  GPIO_InitStruct.Pin = LED1OUT_Pin|LED2OUT_Pin|LED3OUT_Pin|LED4OUT_Pin;
  GPIO_InitStruct.Mode = LL_GPIO_MODE_ALTERNATE;
  GPIO_InitStruct.Speed = LL_GPIO_SPEED_FREQ_LOW;
  GPIO_InitStruct.OutputType = LL_GPIO_OUTPUT_PUSHPULL;
  GPIO_InitStruct.Pull = LL_GPIO_PULL_NO;
  GPIO_InitStruct.Alternate = LL_GPIO_AF_1;
  LL_GPIO_Init(GPIOA, &GPIO_InitStruct);

}

static void MX_TIM3_Init(void)
{

  LL_TIM_InitTypeDef TIM_InitStruct = {0};

  LL_GPIO_InitTypeDef GPIO_InitStruct = {0};

  /* Peripheral clock enable */
  LL_APB1_GRP1_EnableClock(LL_APB1_GRP1_PERIPH_TIM3);

  LL_AHB2_GRP1_EnableClock(LL_AHB2_GRP1_PERIPH_GPIOE);
  /**TIM3 GPIO Configuration
  PE3   ------> TIM3_CH1
  PE4   ------> TIM3_CH2
  */
  GPIO_InitStruct.Pin = ENCODER_A_Pin|ENCODER_B_Pin;
  GPIO_InitStruct.Mode = LL_GPIO_MODE_ALTERNATE;
  GPIO_InitStruct.Speed = LL_GPIO_SPEED_FREQ_LOW;
  GPIO_InitStruct.OutputType = LL_GPIO_OUTPUT_PUSHPULL;
  GPIO_InitStruct.Pull = LL_GPIO_PULL_UP;
  GPIO_InitStruct.Alternate = LL_GPIO_AF_2;
  LL_GPIO_Init(GPIOE, &GPIO_InitStruct);

  TIM_InitStruct.Prescaler = 0;
  TIM_InitStruct.CounterMode = LL_TIM_COUNTERMODE_UP;
  TIM_InitStruct.Autoreload = 4.294967295E9;
  TIM_InitStruct.ClockDivision = LL_TIM_CLOCKDIVISION_DIV1;
  LL_TIM_Init(TIM3, &TIM_InitStruct);
  LL_TIM_DisableARRPreload(TIM3);
  LL_TIM_SetEncoderMode(TIM3, LL_TIM_ENCODERMODE_X4_TI12);
  LL_TIM_IC_SetActiveInput(TIM3, LL_TIM_CHANNEL_CH1, LL_TIM_ACTIVEINPUT_DIRECTTI);
  LL_TIM_IC_SetPrescaler(TIM3, LL_TIM_CHANNEL_CH1, LL_TIM_ICPSC_DIV1);
  LL_TIM_IC_SetFilter(TIM3, LL_TIM_CHANNEL_CH1, LL_TIM_IC_FILTER_FDIV8_N6);
  LL_TIM_IC_SetPolarity(TIM3, LL_TIM_CHANNEL_CH1, LL_TIM_IC_POLARITY_RISING);
  LL_TIM_IC_SetActiveInput(TIM3, LL_TIM_CHANNEL_CH2, LL_TIM_ACTIVEINPUT_DIRECTTI);
  LL_TIM_IC_SetPrescaler(TIM3, LL_TIM_CHANNEL_CH2, LL_TIM_ICPSC_DIV1);
  LL_TIM_IC_SetFilter(TIM3, LL_TIM_CHANNEL_CH2, LL_TIM_IC_FILTER_FDIV8_N6);
  LL_TIM_IC_SetPolarity(TIM3, LL_TIM_CHANNEL_CH2, LL_TIM_IC_POLARITY_RISING);
  LL_TIM_SetTriggerOutput(TIM3, LL_TIM_TRGO_RESET);
  LL_TIM_DisableMasterSlaveMode(TIM3);

}

static void MX_TIM6_Init(void)
{

  LL_TIM_InitTypeDef TIM_InitStruct = {0};

  /* Peripheral clock enable */
  LL_APB1_GRP1_EnableClock(LL_APB1_GRP1_PERIPH_TIM6);

  /* TIM6 interrupt Init */
  NVIC_SetPriority(TIM6_IRQn, NVIC_EncodePriority(NVIC_GetPriorityGrouping(),1, 0));
  NVIC_EnableIRQ(TIM6_IRQn);

  TIM_InitStruct.Prescaler = 15999;
  TIM_InitStruct.CounterMode = LL_TIM_COUNTERMODE_UP;
  TIM_InitStruct.Autoreload = 9;
  LL_TIM_Init(TIM6, &TIM_InitStruct);
  LL_TIM_DisableARRPreload(TIM6);
  LL_TIM_SetTriggerOutput(TIM6, LL_TIM_TRGO_RESET);
  LL_TIM_DisableMasterSlaveMode(TIM6);

}

static void MX_TIM7_Init(void)
{

  LL_TIM_InitTypeDef TIM_InitStruct = {0};

  /* Peripheral clock enable */
  LL_APB1_GRP1_EnableClock(LL_APB1_GRP1_PERIPH_TIM7);

  /* TIM7 interrupt Init */
  NVIC_SetPriority(TIM7_IRQn, NVIC_EncodePriority(NVIC_GetPriorityGrouping(),2, 0));
  NVIC_EnableIRQ(TIM7_IRQn);

  TIM_InitStruct.Prescaler = 15999;
  TIM_InitStruct.CounterMode = LL_TIM_COUNTERMODE_UP;
  TIM_InitStruct.Autoreload = 9;
  LL_TIM_Init(TIM7, &TIM_InitStruct);
  LL_TIM_DisableARRPreload(TIM7);
  LL_TIM_SetTriggerOutput(TIM7, LL_TIM_TRGO_RESET);
  LL_TIM_DisableMasterSlaveMode(TIM7);

}

static void MX_UCPD1_Init(void)
{

  LL_GPIO_InitTypeDef GPIO_InitStruct = {0};

  /* Peripheral clock enable */
  LL_APB1_GRP2_EnableClock(LL_APB1_GRP2_PERIPH_UCPD1);

  LL_AHB2_GRP1_EnableClock(LL_AHB2_GRP1_PERIPH_GPIOB);
  LL_AHB2_GRP1_EnableClock(LL_AHB2_GRP1_PERIPH_GPIOA);
  /**UCPD1 GPIO Configuration
  PB15   ------> UCPD1_CC2
  PA15 (JTDI)   ------> UCPD1_CC1
  */
  GPIO_InitStruct.Pin = UCPD1_CC2_Pin;
  GPIO_InitStruct.Mode = LL_GPIO_MODE_ANALOG;
  GPIO_InitStruct.Pull = LL_GPIO_PULL_NO;
  LL_GPIO_Init(UCPD1_CC2_GPIO_Port, &GPIO_InitStruct);

  GPIO_InitStruct.Pin = UCPD1_CC1_Pin;
  GPIO_InitStruct.Mode = LL_GPIO_MODE_ANALOG;
  GPIO_InitStruct.Pull = LL_GPIO_PULL_NO;
  LL_GPIO_Init(UCPD1_CC1_GPIO_Port, &GPIO_InitStruct);

}

static void MX_USART1_UART_Init(void)
{

  LL_USART_InitTypeDef USART_InitStruct = {0};

  LL_GPIO_InitTypeDef GPIO_InitStruct = {0};

  LL_RCC_SetUSARTClockSource(LL_RCC_USART1_CLKSOURCE_PCLK2);

  /* Peripheral clock enable */
  LL_APB2_GRP1_EnableClock(LL_APB2_GRP1_PERIPH_USART1);

  LL_AHB2_GRP1_EnableClock(LL_AHB2_GRP1_PERIPH_GPIOA);
  /**USART1 GPIO Configuration
  PA9   ------> USART1_TX
  PA10   ------> USART1_RX
  */
  GPIO_InitStruct.Pin = USART1_TX_Pin|USART1_RX_Pin;
  GPIO_InitStruct.Mode = LL_GPIO_MODE_ALTERNATE;
  GPIO_InitStruct.Speed = LL_GPIO_SPEED_FREQ_VERY_HIGH;
  GPIO_InitStruct.OutputType = LL_GPIO_OUTPUT_PUSHPULL;
  GPIO_InitStruct.Pull = LL_GPIO_PULL_DOWN;
  GPIO_InitStruct.Alternate = LL_GPIO_AF_7;
  LL_GPIO_Init(GPIOA, &GPIO_InitStruct);

  USART_InitStruct.PrescalerValue = LL_USART_PRESCALER_DIV1;
  USART_InitStruct.BaudRate = 115200;
  USART_InitStruct.DataWidth = LL_USART_DATAWIDTH_8B;
  USART_InitStruct.StopBits = LL_USART_STOPBITS_1;
  USART_InitStruct.Parity = LL_USART_PARITY_NONE;
  USART_InitStruct.TransferDirection = LL_USART_DIRECTION_TX_RX;
  USART_InitStruct.HardwareFlowControl = LL_USART_HWCONTROL_NONE;
  USART_InitStruct.OverSampling = LL_USART_OVERSAMPLING_16;
  LL_USART_Init(USART1, &USART_InitStruct);
  LL_USART_SetTXFIFOThreshold(USART1, LL_USART_FIFOTHRESHOLD_1_8);
  LL_USART_SetRXFIFOThreshold(USART1, LL_USART_FIFOTHRESHOLD_1_8);
  LL_USART_DisableFIFO(USART1);
  LL_USART_ConfigAsyncMode(USART1);
  LL_USART_Enable(USART1);

}

static void MX_USB_OTG_FS_PCD_Init(void)
{

  hpcd_USB_OTG_FS.Instance = USB_OTG_FS;
  hpcd_USB_OTG_FS.Init.dev_endpoints = 6;
  hpcd_USB_OTG_FS.Init.speed = PCD_SPEED_FULL;
  hpcd_USB_OTG_FS.Init.phy_itface = PCD_PHY_EMBEDDED;
  hpcd_USB_OTG_FS.Init.Sof_enable = DISABLE;
  hpcd_USB_OTG_FS.Init.low_power_enable = DISABLE;
  hpcd_USB_OTG_FS.Init.lpm_enable = DISABLE;
  hpcd_USB_OTG_FS.Init.battery_charging_enable = DISABLE;
  hpcd_USB_OTG_FS.Init.use_dedicated_ep1 = DISABLE;
  hpcd_USB_OTG_FS.Init.vbus_sensing_enable = DISABLE;
  hpcd_USB_OTG_FS.Init.dma_enable = DISABLE;
  if (HAL_PCD_Init(&hpcd_USB_OTG_FS) != HAL_OK)
  {
    Error_Handler();
  }

}

static void MX_GPIO_Init(void)
{
  LL_EXTI_InitTypeDef EXTI_InitStruct = {0};
  LL_GPIO_InitTypeDef GPIO_InitStruct = {0};

  /* GPIO Ports Clock Enable */
  LL_AHB2_GRP1_EnableClock(LL_AHB2_GRP1_PERIPH_GPIOE);
  LL_AHB2_GRP1_EnableClock(LL_AHB2_GRP1_PERIPH_GPIOC);
  LL_AHB2_GRP1_EnableClock(LL_AHB2_GRP1_PERIPH_GPIOA);
  LL_AHB2_GRP1_EnableClock(LL_AHB2_GRP1_PERIPH_GPIOF);
  LL_AHB2_GRP1_EnableClock(LL_AHB2_GRP1_PERIPH_GPIOB);
  LL_AHB2_GRP1_EnableClock(LL_AHB2_GRP1_PERIPH_GPIOD);
  LL_AHB2_GRP1_EnableClock(LL_AHB2_GRP1_PERIPH_GPIOG);
  LL_PWR_EnableVDDIO2();

  /**/
  LL_GPIO_ResetOutputPin(GPIOD, OLED1CS_Pin|OLED2CS_Pin|OLEDDC_Pin|OLEDRES_Pin
                          |LL_GPIO_PIN_14);

  /**/
  LL_GPIO_ResetOutputPin(LED_RED_GPIO_Port, LED_RED_Pin);

  /**/
  LL_GPIO_ResetOutputPin(LED_GREEN_GPIO_Port, LED_GREEN_Pin);

  /**/
  LL_GPIO_ResetOutputPin(GPIOB, UCPD_DBn_Pin|LED_BLUE_Pin);

  /**/
  LL_EXTI_SetEXTISource(LL_EXTI_EXTI_PORTE, LL_EXTI_EXTI_LINE5);

  /**/
  EXTI_InitStruct.Line_0_31 = LL_EXTI_LINE_5;
  EXTI_InitStruct.LineCommand = ENABLE;
  EXTI_InitStruct.Mode = LL_EXTI_MODE_IT;
  EXTI_InitStruct.Trigger = LL_EXTI_TRIGGER_FALLING;
  LL_EXTI_Init(&EXTI_InitStruct);

  /**/
  LL_GPIO_SetPinPull(ENCODER_SW_GPIO_Port, ENCODER_SW_Pin, LL_GPIO_PULL_UP);

  /**/
  LL_GPIO_SetPinMode(ENCODER_SW_GPIO_Port, ENCODER_SW_Pin, LL_GPIO_MODE_INPUT);

  /**/
  GPIO_InitStruct.Pin = LDR1IN_Pin;
  GPIO_InitStruct.Mode = LL_GPIO_MODE_INPUT;
  GPIO_InitStruct.Pull = LL_GPIO_PULL_NO;
  LL_GPIO_Init(LDR1IN_GPIO_Port, &GPIO_InitStruct);

  /**/
  GPIO_InitStruct.Pin = LL_GPIO_PIN_4|LL_GPIO_PIN_5|LL_GPIO_PIN_6|LL_GPIO_PIN_7;
  GPIO_InitStruct.Mode = LL_GPIO_MODE_INPUT;
  GPIO_InitStruct.Pull = LL_GPIO_PULL_UP;
  LL_GPIO_Init(GPIOA, &GPIO_InitStruct);

  /**/
  GPIO_InitStruct.Pin = LDR2IN_Pin|LDR3IN_Pin|LDR4IN_Pin;
  GPIO_InitStruct.Mode = LL_GPIO_MODE_INPUT;
  GPIO_InitStruct.Pull = LL_GPIO_PULL_NO;
  LL_GPIO_Init(GPIOF, &GPIO_InitStruct);

  /**/
  GPIO_InitStruct.Pin = UCPD_FLT_Pin;
  GPIO_InitStruct.Mode = LL_GPIO_MODE_INPUT;
  GPIO_InitStruct.Pull = LL_GPIO_PULL_NO;
  LL_GPIO_Init(UCPD_FLT_GPIO_Port, &GPIO_InitStruct);

  /**/
  GPIO_InitStruct.Pin = OLED1CS_Pin|OLED2CS_Pin|OLEDDC_Pin|OLEDRES_Pin
                          |LL_GPIO_PIN_14;
  GPIO_InitStruct.Mode = LL_GPIO_MODE_OUTPUT;
  GPIO_InitStruct.Speed = LL_GPIO_SPEED_FREQ_LOW;
  GPIO_InitStruct.OutputType = LL_GPIO_OUTPUT_PUSHPULL;
  GPIO_InitStruct.Pull = LL_GPIO_PULL_NO;
  LL_GPIO_Init(GPIOD, &GPIO_InitStruct);

  /**/
  GPIO_InitStruct.Pin = LED_RED_Pin;
  GPIO_InitStruct.Mode = LL_GPIO_MODE_OUTPUT;
  GPIO_InitStruct.Speed = LL_GPIO_SPEED_FREQ_HIGH;
  GPIO_InitStruct.OutputType = LL_GPIO_OUTPUT_PUSHPULL;
  GPIO_InitStruct.Pull = LL_GPIO_PULL_UP;
  LL_GPIO_Init(LED_RED_GPIO_Port, &GPIO_InitStruct);

  /**/
  GPIO_InitStruct.Pin = LED_GREEN_Pin;
  GPIO_InitStruct.Mode = LL_GPIO_MODE_OUTPUT;
  GPIO_InitStruct.Speed = LL_GPIO_SPEED_FREQ_HIGH;
  GPIO_InitStruct.OutputType = LL_GPIO_OUTPUT_PUSHPULL;
  GPIO_InitStruct.Pull = LL_GPIO_PULL_UP;
  LL_GPIO_Init(LED_GREEN_GPIO_Port, &GPIO_InitStruct);

  /**/
  GPIO_InitStruct.Pin = UCPD_DBn_Pin;
  GPIO_InitStruct.Mode = LL_GPIO_MODE_OUTPUT;
  GPIO_InitStruct.Speed = LL_GPIO_SPEED_FREQ_LOW;
  GPIO_InitStruct.OutputType = LL_GPIO_OUTPUT_PUSHPULL;
  GPIO_InitStruct.Pull = LL_GPIO_PULL_NO;
  LL_GPIO_Init(UCPD_DBn_GPIO_Port, &GPIO_InitStruct);

  /**/
  GPIO_InitStruct.Pin = LED_BLUE_Pin;
  GPIO_InitStruct.Mode = LL_GPIO_MODE_OUTPUT;
  GPIO_InitStruct.Speed = LL_GPIO_SPEED_FREQ_HIGH;
  GPIO_InitStruct.OutputType = LL_GPIO_OUTPUT_PUSHPULL;
  GPIO_InitStruct.Pull = LL_GPIO_PULL_UP;
  LL_GPIO_Init(LED_BLUE_GPIO_Port, &GPIO_InitStruct);

  /* EXTI interrupt init*/
  NVIC_SetPriority(EXTI5_IRQn, NVIC_EncodePriority(NVIC_GetPriorityGrouping(),3, 0));
  NVIC_EnableIRQ(EXTI5_IRQn);

}

void Error_Handler(void)
{
  __disable_irq();
  while (1)
  {
  }
}
